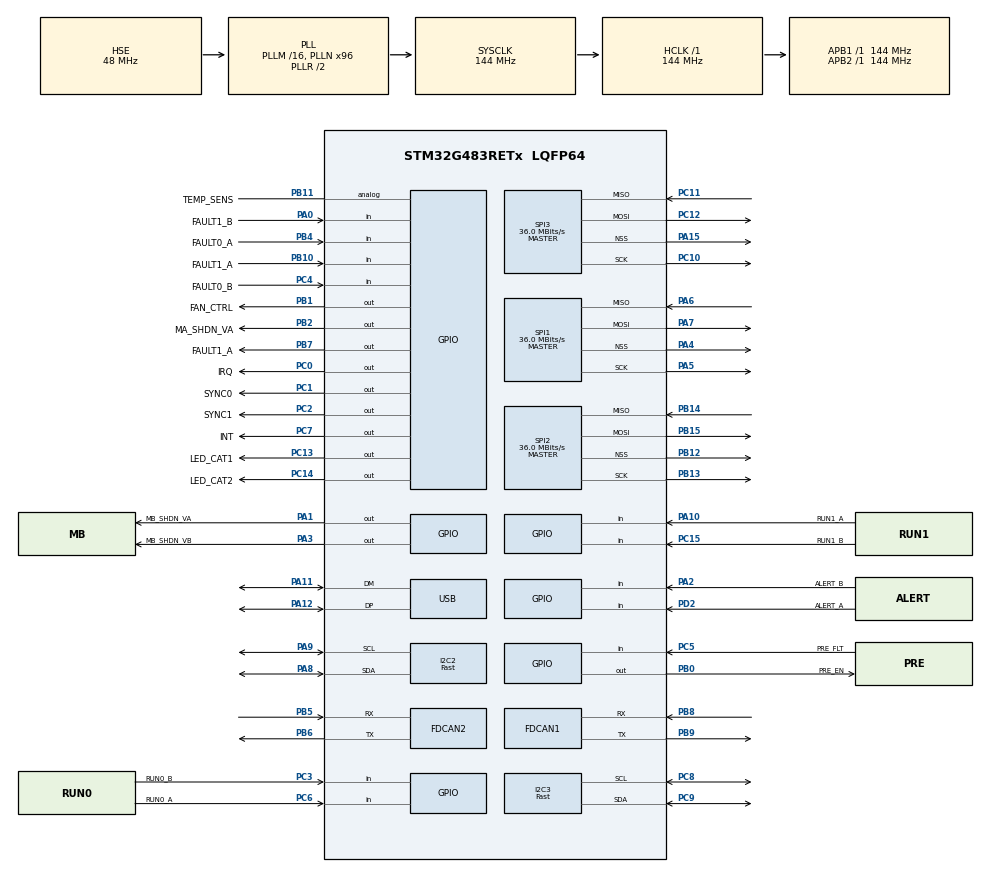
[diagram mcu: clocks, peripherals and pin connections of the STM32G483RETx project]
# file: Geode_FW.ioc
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CRC.CRCLength=CRC_POLYLENGTH_16B
CRC.DefaultInitValueUse=DEFAULT_INIT_VALUE_DISABLE
CRC.DefaultPolynomialUse=DEFAULT_POLYNOMIAL_DISABLE
CRC.InitValue=0xFFFF
FDCAN1.CalculateBaudRateNominal=1800000
FDCAN1.CalculateTimeBitNominal=555
FDCAN1.CalculateTimeQuantumNominal=111.11111111111111
FDCAN2.CalculateBaudRateNominal=1800000
FDCAN2.CalculateTimeBitNominal=555
FDCAN2.CalculateTimeQuantumNominal=111.11111111111111
FREERTOS.Tasks01=defaultTask,24,128,StartDefaultTask,Default,NULL,Dynamic,NULL,NULL
FREERTOS.configENABLE_FPU=1
FREERTOS.configTOTAL_HEAP_SIZE=61440
FREERTOS.configUSE_NEWLIB_REENTRANT=1
I2C2.I2C_Speed_Mode=I2C_Fast
I2C2.Timing=0x00E057FD
I2C3.I2C_Speed_Mode=I2C_Fast
I2C3.Timing=0x00E057FD
Mcu.Family=STM32G4
Mcu.Name=STM32G483RETx
Mcu.Package=LQFP64
NVIC.PriorityGroup=NVIC_PRIORITYGROUP_4
NVIC.USB_LP_IRQn=true\:5\:0\:false\:false\:true\:true\:false\:true\:true
PA0.GPIO_Label=FAULT1_B
PA0.Signal=GPIO_Input
PA1.GPIO_Label=MB_SHDN_VA
PA1.Signal=GPIO_Output
PA10.GPIO_Label=RUN1_A
PA10.Signal=GPIO_Input
PA11.Mode=Device
PA11.Signal=USB_DM
PA12.Mode=Device
PA12.Signal=USB_DP
PA13.Mode=Trace_Asynchronous_SW
PA13.Signal=SYS_JTMS-SWDIO
PA14.Mode=Trace_Asynchronous_SW
PA14.Signal=SYS_JTCK-SWCLK
PA15.Mode=NSS_Signal_Hard_Output
PA15.Signal=SPI3_NSS
PA2.GPIO_Label=ALERT_B
PA2.Signal=GPIO_Input
PA3.GPIO_Label=MB_SHDN_VB
PA3.Signal=GPIO_Output
PA4.Mode=NSS_Signal_Hard_Output
PA4.Signal=SPI1_NSS
PA5.Mode=Full_Duplex_Master
PA5.Signal=SPI1_SCK
PA6.Mode=Full_Duplex_Master
PA6.Signal=SPI1_MISO
PA7.Mode=Full_Duplex_Master
PA7.Signal=SPI1_MOSI
PA8.Mode=I2C
PA8.Signal=I2C2_SDA
PA9.Mode=I2C
PA9.Signal=I2C2_SCL
PB0.GPIO_Label=PRE_EN
PB0.Signal=GPIO_Output
PB1.GPIO_Label=FAN_CTRL
PB1.Signal=GPIO_Output
PB10.GPIO_Label=FAULT1_A
PB10.Signal=GPIO_Input
PB11.GPIO_Label=TEMP_SENS
PB11.Signal=GPIO_Analog
PB12.Mode=NSS_Signal_Hard_Output
PB12.Signal=SPI2_NSS
PB13.Mode=Full_Duplex_Master
PB13.Signal=SPI2_SCK
PB14.Mode=Full_Duplex_Master
PB14.Signal=SPI2_MISO
PB15.Mode=Full_Duplex_Master
PB15.Signal=SPI2_MOSI
PB2.GPIO_Label=MA_SHDN_VA
PB2.Signal=GPIO_Output
PB3.Mode=Trace_Asynchronous_SW
PB3.Signal=SYS_JTDO-SWO
PB4.GPIO_Label=FAULT0_A
PB4.Signal=GPIO_Input
PB5.Mode=FDCAN_Activate
PB5.Signal=FDCAN2_RX
PB6.Mode=FDCAN_Activate
PB6.Signal=FDCAN2_TX
PB7.GPIO_Label=FAULT1_A
PB7.Signal=GPIO_Output
PB8-BOOT0.Mode=FDCAN_Activate
PB8-BOOT0.Signal=FDCAN1_RX
PB9.Mode=FDCAN_Activate
PB9.Signal=FDCAN1_TX
PC0.GPIO_Label=IRQ
PC0.Signal=GPIO_Output
PC1.GPIO_Label=SYNC0
PC1.Signal=GPIO_Output
PC10.Mode=Full_Duplex_Master
PC10.Signal=SPI3_SCK
PC11.Mode=Full_Duplex_Master
PC11.Signal=SPI3_MISO
PC12.Mode=Full_Duplex_Master
PC12.Signal=SPI3_MOSI
PC13.GPIO_Label=LED_CAT1
PC13.Signal=GPIO_Output
PC14-OSC32_IN.GPIO_Label=LED_CAT2
PC14-OSC32_IN.Signal=GPIO_Output
PC15-OSC32_OUT.GPIO_Label=RUN1_B
PC15-OSC32_OUT.Signal=GPIO_Input
PC2.GPIO_Label=SYNC1
PC2.Signal=GPIO_Output
PC3.GPIO_Label=RUN0_B
PC3.Signal=GPIO_Input
PC4.GPIO_Label=FAULT0_B
PC4.Signal=GPIO_Input
PC5.GPIO_Label=PRE_FLT
PC5.Signal=GPIO_Input
PC6.GPIO_Label=RUN0_A
PC6.Signal=GPIO_Input
PC7.GPIO_Label=INT
PC7.Signal=GPIO_Output
PC8.Mode=I2C
PC8.Signal=I2C3_SCL
PC9.Mode=I2C
PC9.Signal=I2C3_SDA
PD2.GPIO_Label=ALERT_A
PD2.Signal=GPIO_Input
PF0-OSC_IN.Mode=HSE-External-Oscillator
PF0-OSC_IN.Signal=RCC_OSC_IN
PF1-OSC_OUT.Mode=HSE-External-Oscillator
PF1-OSC_OUT.Signal=RCC_OSC_OUT
ProjectManager.HeapSize=0x200
ProjectManager.StackSize=0x400
ProjectManager.TargetToolchain=STM32CubeIDE
RCC.ADC12Freq_Value=144000000
RCC.ADC345Freq_Value=144000000
RCC.AHBFreq_Value=144000000
RCC.APB1Freq_Value=144000000
RCC.APB1TimFreq_Value=144000000
RCC.APB2Freq_Value=144000000
RCC.APB2TimFreq_Value=144000000
RCC.CortexFreq_Value=144000000
RCC.EXTERNAL_CLOCK_VALUE=12288000
RCC.HCLKFreq_Value=144000000
RCC.HSE_VALUE=48000000
RCC.HSI48_VALUE=48000000
RCC.HSI_VALUE=16000000
RCC.LSE_VALUE=32768
RCC.PLLM=RCC_PLLM_DIV16
RCC.PLLN=96
RCC.PLLQ=RCC_PLLQ_DIV6
RCC.PLLSourceVirtual=RCC_PLLSOURCE_HSE
RCC.SYSCLKFreq_VALUE=144000000
RCC.SYSCLKSource=RCC_SYSCLKSOURCE_PLLCLK
RCC.USBFreq_Value=48000000
RCC.VCOOutputFreq_Value=288000000
SPI1.BaudRatePrescaler=SPI_BAUDRATEPRESCALER_4
SPI1.CLKPhase=SPI_PHASE_2EDGE
SPI1.CLKPolarity=SPI_POLARITY_HIGH
SPI1.CalculateBaudRate=36.0 MBits/s
SPI1.DataSize=SPI_DATASIZE_8BIT
SPI1.Direction=SPI_DIRECTION_2LINES
SPI1.Mode=SPI_MODE_MASTER
SPI1.VirtualNSS=VM_NSSHARD
SPI1.VirtualType=VM_MASTER
SPI2.BaudRatePrescaler=SPI_BAUDRATEPRESCALER_4
SPI2.CLKPhase=SPI_PHASE_2EDGE
SPI2.CLKPolarity=SPI_POLARITY_HIGH
SPI2.CalculateBaudRate=36.0 MBits/s
SPI2.DataSize=SPI_DATASIZE_8BIT
SPI2.Direction=SPI_DIRECTION_2LINES
SPI2.Mode=SPI_MODE_MASTER
SPI2.VirtualNSS=VM_NSSHARD
SPI2.VirtualType=VM_MASTER
SPI3.BaudRatePrescaler=SPI_BAUDRATEPRESCALER_4
SPI3.CLKPhase=SPI_PHASE_2EDGE
SPI3.CLKPolarity=SPI_POLARITY_HIGH
SPI3.CalculateBaudRate=36.0 MBits/s
SPI3.DataSize=SPI_DATASIZE_8BIT
SPI3.Direction=SPI_DIRECTION_2LINES
SPI3.Mode=SPI_MODE_MASTER
SPI3.VirtualNSS=VM_NSSHARD
SPI3.VirtualType=VM_MASTER
USB_DEVICE.CLASS_NAME_FS=CDC
USB_DEVICE.VirtualMode=Cdc
USB_DEVICE.VirtualModeFS=Cdc_FS
VP_CRC_VS_CRC.Mode=CRC_Activate
VP_FREERTOS_VS_CMSIS_V2.Mode=CMSIS_V2
VP_IWDG_VS_IWDG.Mode=IWDG_Activate
VP_USB_DEVICE_VS_USB_DEVICE_CDC_FS.Mode=CDC_FS
board=custom

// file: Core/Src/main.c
/* USER CODE BEGIN Header */
/**
  ******************************************************************************
  * @file           : main.c
  * @brief          : Main program body
  ******************************************************************************
  * @attention
  *
  * Copyright (c) 2024 STMicroelectronics.
  * All rights reserved.
  *
  * This software is licensed under terms that can be found in the LICENSE file
  * in the root directory of this software component.
  * If no LICENSE file comes with this software, it is provided AS-IS.
  *
  ******************************************************************************
  */
/* USER CODE END Header */
#include "main.h"
#include "cmsis_os.h"
#include "crc.h"
#include "fdcan.h"
#include "i2c.h"
#include "iwdg.h"
#include "spi.h"
#include "usb_device.h"
#include "gpio.h"

void SystemClock_Config(void);
void MX_FREERTOS_Init(void);

int main(void)
{

  /* MCU Configuration--------------------------------------------------------*/

  /* Reset of all peripherals, Initializes the Flash interface and the Systick. */
  HAL_Init();

  /* Configure the system clock */
  SystemClock_Config();

  /* Initialize all configured peripherals */
  MX_GPIO_Init();
  MX_CRC_Init();
  MX_FDCAN1_Init();
  MX_FDCAN2_Init();
  MX_I2C2_Init();
  MX_I2C3_Init();
  MX_IWDG_Init();
  MX_SPI1_Init();
  MX_SPI2_Init();
  MX_SPI3_Init();
  MX_USB_Device_Init();

  /* Init scheduler */
  osKernelInitialize();  /* Call init function for freertos objects (in freertos.c) */
  MX_FREERTOS_Init();

  /* Start scheduler */
  osKernelStart();

  /* We should never get here as control is now taken by the scheduler */
  /* Infinite loop */
  while (1)
  {

  }
}

void SystemClock_Config(void)
{
  RCC_OscInitTypeDef RCC_OscInitStruct = {0};
  RCC_ClkInitTypeDef RCC_ClkInitStruct = {0};

  /** Configure the main internal regulator output voltage
  */
  HAL_PWREx_ControlVoltageScaling(PWR_REGULATOR_VOLTAGE_SCALE1);

  /** Initializes the RCC Oscillators according to the specified parameters
  * in the RCC_OscInitTypeDef structure.
  */
  RCC_OscInitStruct.OscillatorType = RCC_OSCILLATORTYPE_LSI|RCC_OSCILLATORTYPE_HSE;
  RCC_OscInitStruct.HSEState = RCC_HSE_ON;
  RCC_OscInitStruct.LSIState = RCC_LSI_ON;
  RCC_OscInitStruct.PLL.PLLState = RCC_PLL_ON;
  RCC_OscInitStruct.PLL.PLLSource = RCC_PLLSOURCE_HSE;
  RCC_OscInitStruct.PLL.PLLM = RCC_PLLM_DIV16;
  RCC_OscInitStruct.PLL.PLLN = 96;
  RCC_OscInitStruct.PLL.PLLP = RCC_PLLP_DIV2;
  RCC_OscInitStruct.PLL.PLLQ = RCC_PLLQ_DIV6;
  RCC_OscInitStruct.PLL.PLLR = RCC_PLLR_DIV2;
  if (HAL_RCC_OscConfig(&RCC_OscInitStruct) != HAL_OK)
  {
    Error_Handler();
  }

  /** Initializes the CPU, AHB and APB buses clocks
  */
  RCC_ClkInitStruct.ClockType = RCC_CLOCKTYPE_HCLK|RCC_CLOCKTYPE_SYSCLK
                              |RCC_CLOCKTYPE_PCLK1|RCC_CLOCKTYPE_PCLK2;
  RCC_ClkInitStruct.SYSCLKSource = RCC_SYSCLKSOURCE_PLLCLK;
  RCC_ClkInitStruct.AHBCLKDivider = RCC_SYSCLK_DIV1;
  RCC_ClkInitStruct.APB1CLKDivider = RCC_HCLK_DIV1;
  RCC_ClkInitStruct.APB2CLKDivider = RCC_HCLK_DIV1;

  if (HAL_RCC_ClockConfig(&RCC_ClkInitStruct, FLASH_LATENCY_4) != HAL_OK)
  {
    Error_Handler();
  }
}

void Error_Handler(void)
{
  __disable_irq();
  while (1)
  {
  }
}

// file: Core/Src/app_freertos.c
/* USER CODE BEGIN Header */
/**
  ******************************************************************************
  * File Name          : app_freertos.c
  * Description        : Code for freertos applications
  ******************************************************************************
  * @attention
  *
  * Copyright (c) 2024 STMicroelectronics.
  * All rights reserved.
  *
  * This software is licensed under terms that can be found in the LICENSE file
  * in the root directory of this software component.
  * If no LICENSE file comes with this software, it is provided AS-IS.
  *
  ******************************************************************************
  */
/* USER CODE END Header */

#include "FreeRTOS.h"
#include "task.h"
#include "main.h"
#include "cmsis_os.h"

/* USER CODE BEGIN Includes */
//#include "../../System/Kernel/Inc/Kernel.h"

/* USER CODE END Includes */

/* Definitions for defaultTask */
osThreadId_t defaultTaskHandle;
const osThreadAttr_t defaultTask_attributes = {
  .name = "defaultTask",
  .priority = (osPriority_t) osPriorityNormal,
  .stack_size = 128 * 4
};

void StartDefaultTask(void *argument);

void MX_FREERTOS_Init(void); /* (MISRA C 2004 rule 8.1) */

void MX_FREERTOS_Init(void) {

  /* Create the thread(s) */
  /* creation of defaultTask */
  defaultTaskHandle = osThreadNew(StartDefaultTask, NULL, &defaultTask_attributes);

}

void StartDefaultTask(void *argument)
{
  for(;;)
  {
    osDelay(1);
  }
}
